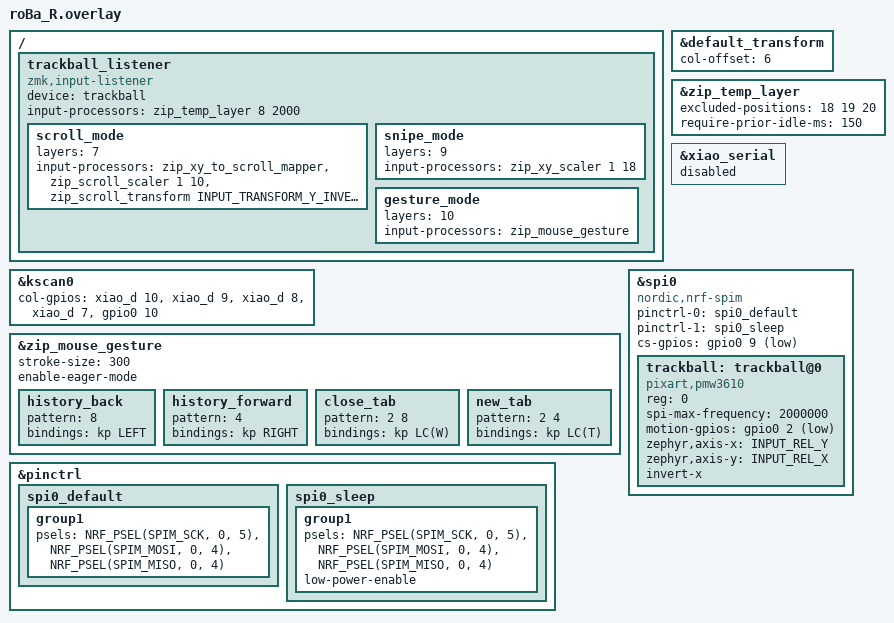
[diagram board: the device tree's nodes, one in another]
#include "roBa.dtsi"
#include <input/processors.dtsi>
#include <dt-bindings/zmk/input_transform.h>
#include <dt-bindings/zmk/keys.h>
#include <mouse-gesture.dtsi>
#include <zephyr/dt-bindings/input/input-event-codes.h>

&default_transform {
    col-offset = <6>;
};

&kscan0 {
    col-gpios
        = <&xiao_d 10 GPIO_ACTIVE_HIGH>
        , <&xiao_d 9 GPIO_ACTIVE_HIGH>
        , <&xiao_d 8 GPIO_ACTIVE_HIGH>
        , <&xiao_d 7 GPIO_ACTIVE_HIGH>
        , <&gpio0 10 GPIO_ACTIVE_HIGH>
        ;
};

&zip_temp_layer {
    excluded-positions = <
        18 // J
        19 // K
        20 // L
    >;

    require-prior-idle-ms = <150>;
};

/ {
    trackball_listener {
        status = "okay";
        compatible = "zmk,input-listener";
        device = <&trackball>;

        /*
         * 通常時：
         * トラックボールを動かすとLayer 8を一時的に有効化
         */
        input-processors =
            <&zip_temp_layer 8 2000>;

        /*
         * Layer 7：スクロール
         */
        scroll_mode {
            layers = <7>;

            input-processors =
                <&zip_xy_to_scroll_mapper>,
                <&zip_scroll_scaler 1 10>,
                <&zip_scroll_transform INPUT_TRANSFORM_Y_INVERT>;
        };

        /*
         * Layer 9：スナイプ
         */
        snipe_mode {
            layers = <9>;

            input-processors =
                <&zip_xy_scaler 1 18>;
        };

        /*
         * Layer 10：マウスジェスチャー
         *
         * Layer 10が有効なときだけ、
         * トラックボールのXY入力をジェスチャーとして処理する。
         */
        gesture_mode {
            layers = <10>;

            input-processors =
                <&zip_mouse_gesture>;
        };
    };
};

/*
 * マウスジェスチャー設定
 */
&zip_mouse_gesture {
    /*
     * 1ストロークとして認識する移動量
     * デフォルト200 → 300
     */
    stroke-size = <300>;

    /*
     * パターンが完成したらすぐ実行
     */
    enable-eager-mode;

history_back {
    pattern = <8>;
    bindings = <&kp LEFT>;
};

history_forward {
    pattern = <4>;
    bindings = <&kp RIGHT>;
};

close_tab {
    pattern = <2 8>;
    bindings = <&kp LC(W)>;
};

new_tab {
    pattern = <2 4>;
    bindings = <&kp LC(T)>;
};
};

&pinctrl {
    spi0_default: spi0_default {
        group1 {
            psels = <NRF_PSEL(SPIM_SCK, 0, 5)>,
                <NRF_PSEL(SPIM_MOSI, 0, 4)>,
                <NRF_PSEL(SPIM_MISO, 0, 4)>;
        };
    };

    spi0_sleep: spi0_sleep {
        group1 {
            psels = <NRF_PSEL(SPIM_SCK, 0, 5)>,
                <NRF_PSEL(SPIM_MOSI, 0, 4)>,
                <NRF_PSEL(SPIM_MISO, 0, 4)>;
            low-power-enable;
        };
    };
};

&xiao_serial {
    status = "disabled";
};

&spi0 {
    status = "okay";
    compatible = "nordic,nrf-spim";
    pinctrl-0 = <&spi0_default>;
    pinctrl-1 = <&spi0_sleep>;
    pinctrl-names = "default", "sleep";
    cs-gpios = <&gpio0 9 GPIO_ACTIVE_LOW>;

    trackball: trackball@0 {
        status = "okay";
        compatible = "pixart,pmw3610";
        reg = <0>;
        spi-max-frequency = <2000000>;
        motion-gpios = <&gpio0 2 (GPIO_ACTIVE_LOW | GPIO_PULL_UP)>;

        zephyr,axis-x = <INPUT_REL_Y>;
        zephyr,axis-y = <INPUT_REL_X>;
        invert-x;
    };
};
```
